# LargeDummyDevice register map
File version: 1.0
Registers are 32-bit, read-write, no defined reset value unless marked. A register's access mark holds for its fields unless they carry their own. Offsets are from the block's base; [hi:lo] are bit positions.

## PERIPHERAL_57
Base 0x40038000
0x04 REG_1 — Register 1
  [34:31] FIELD_1, [31:29] FIELD_4, [32:29] FIELD_6, [27:24] FIELD_5, [8] FIELD_2, [10:8] FIELD_3
0x08 REG_2 — Register 2
  [32:31] FIELD_2, [31] FIELD_11, [33:29] FIELD_4, [30:29] FIELD_13, [27:24] FIELD_18, [23] FIELD_12, [25:22] FIELD_5, [22] FIELD_16, [21] FIELD_3, [15:13] FIELD_15, [12] FIELD_17, [14:10] FIELD_10, [11:9] FIELD_14, [12:8] FIELD_7, [9:7] FIELD_1, [10:6] FIELD_19, [7:4] FIELD_8, [5:3] FIELD_6, [6:2] FIELD_9
0x0C REG_3 — Register 3
  [29:28] FIELD_4, [26:23] FIELD_6, [25:22] FIELD_7, [13:12] FIELD_3, [13:11] FIELD_2, [5] FIELD_1, [4:2] FIELD_5, [2:0] FIELD_8, [0] FIELD_9
0x10 REG_4 — Register 4
  [31] FIELD_4, [34:30] FIELD_23, [26:23] FIELD_13, [24:22] FIELD_20, [24:21] FIELD_18, [19:18] FIELD_22, [20:17] FIELD_2, [16:15] FIELD_7, [15] FIELD_15, [16:12] FIELD_9, [16:12] FIELD_12, [13:9] FIELD_10, [10:8] FIELD_11, [11:8] FIELD_21, [7:5] FIELD_14, [7:4] FIELD_3, [8:4] FIELD_8, [6:3] FIELD_1, [3:2] FIELD_5, [6:2] FIELD_6, [3:2] FIELD_17, [4:1] FIELD_16, [2:1] FIELD_19
0x14 REG_5 — Register 5
  [20] FIELD_8, [23:19] FIELD_6, [19:18] FIELD_4, [18:16] FIELD_1, [12:11] FIELD_5, [12:11] FIELD_9, [14:10] FIELD_7, [12:9] FIELD_3, [10:8] FIELD_2
0x18 REG_6 — Register 6
  [20:18] FIELD_4, [18:17] FIELD_3, [13] FIELD_7, [13:11] FIELD_6, [12:10] FIELD_5, [10:9] FIELD_2, [10:6] FIELD_1
0x1C REG_7 — Register 7
  [27:26] FIELD_16, [23] FIELD_9, [23:22] FIELD_3, [22:19] FIELD_14, [19:18] FIELD_1, [18:15] FIELD_8, [16:14] FIELD_5, [13:12] FIELD_12, [15:12] FIELD_15, [13:10] FIELD_7, [14:10] FIELD_13, [9] FIELD_6, [11:7] FIELD_11, [5] FIELD_2, [3:2] FIELD_4, [3:2] FIELD_10
0x20 REG_8 — Register 8
  [30:28] FIELD_1, [27:26] FIELD_2, [26:24] FIELD_11, [24] FIELD_17, [23] FIELD_9, [26:22] FIELD_14, [22:21] FIELD_18, [24:20] FIELD_4, [20:18] FIELD_10, [20:18] FIELD_13, [19:16] FIELD_6, [19:16] FIELD_15, [14:12] FIELD_16, [10] FIELD_5, [8] FIELD_12, [7:4] FIELD_8, [4:1] FIELD_3, [4:1] FIELD_7
0x24 REG_9 — Register 9
  [32:28] FIELD_15, [27] FIELD_7, [28:25] FIELD_5, [24] FIELD_14, [24:23] FIELD_9, [27:23] FIELD_12, [21] FIELD_11, [21:20] FIELD_8, [22:19] FIELD_20, [19] FIELD_23, [17:14] FIELD_4, [18:14] FIELD_6, [16:12] FIELD_2, [16:12] FIELD_16, [15:11] FIELD_17, [9] FIELD_3, [6] FIELD_13, [9:6] FIELD_18, [6:5] FIELD_1, [6:4] FIELD_19, [8:4] FIELD_21, [2:1] FIELD_10, [4:0] FIELD_22
0x28 REG_10 — Register 10
  [31:28] FIELD_3, [32:28] FIELD_8, [28:27] FIELD_10, [26:22] FIELD_11, [22:20] FIELD_6, [21:20] FIELD_9, [19] FIELD_4, [16:15] FIELD_2, [15:14] FIELD_13, [15:11] FIELD_7, [9] FIELD_12, [6] FIELD_1, [7:5] FIELD_5
0x2C REG_11 — Register 11
  [33:31] FIELD_14, [30:29] FIELD_16, [31:28] FIELD_1, [30:27] FIELD_4, [27:26] FIELD_12, [23:22] FIELD_15, [23:21] FIELD_5, [21:19] FIELD_9, [15] FIELD_7, [12] FIELD_11, [11:10] FIELD_3, [11:10] FIELD_13, [12:9] FIELD_8, [12:9] FIELD_18, [9:8] FIELD_2, [6:2] FIELD_10, [1] FIELD_6, [2:0] FIELD_17
0x30 REG_12 — Register 12
  [33:29] FIELD_2, [21:19] FIELD_4, [7] FIELD_3, [7:4] FIELD_1
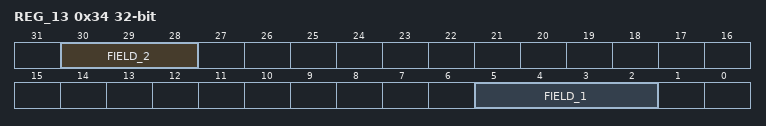
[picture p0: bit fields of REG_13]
0x34 REG_13 — Register 13
  [30:28] FIELD_2, [5:2] FIELD_1
0x38 REG_14 — Register 14
  [31] FIELD_19, [31:28] FIELD_11, [31:27] FIELD_15, [30:27] FIELD_18, [24:22] FIELD_16, [24:20] FIELD_2, [20] FIELD_8, [21:19] FIELD_4, [22:18] FIELD_5, [21:18] FIELD_7, [20:18] FIELD_9, [19:17] FIELD_14, [15] FIELD_12, [14] FIELD_3, [16:14] FIELD_22, [14:13] FIELD_1, [15:13] FIELD_20, [12] FIELD_6, [11] FIELD_21, [9:5] FIELD_10, [6:5] FIELD_13, [2] FIELD_17
0x3C REG_15 — Register 15
  [23] FIELD_1
0x40 REG_16 — Register 16
  [31:28] FIELD_14, [32:28] FIELD_20, [31:27] FIELD_18, [26:25] FIELD_21, [23] FIELD_2, [21] FIELD_4, [21] FIELD_10, [22:20] FIELD_3, [16:13] FIELD_1, [15:12] FIELD_6, [15:12] FIELD_8, [14:12] FIELD_16, [10] FIELD_17, [10:7] FIELD_15, [10:6] FIELD_5, [10:6] FIELD_11, [6:4] FIELD_7, [8:4] FIELD_13, [4:2] FIELD_12, [2] FIELD_19, [4:1] FIELD_9
0x44 REG_17 — Register 17
  [31] FIELD_7, [31] FIELD_16, [31:30] FIELD_25, [30:29] FIELD_27, [30:28] FIELD_10, [31:28] FIELD_13, [31:28] FIELD_28, [31:27] FIELD_4, [28:26] FIELD_1, [27:25] FIELD_20, [25:23] FIELD_15, [20] FIELD_11, [20] FIELD_24, [20:16] FIELD_23, [15] FIELD_9, [14] FIELD_5, [16:14] FIELD_22, [14:13] FIELD_2, [13] FIELD_6, [12] FIELD_12, [9] FIELD_21, [6:5] FIELD_8, [5:4] FIELD_3, [5:3] FIELD_17, [3] FIELD_18, [0] FIELD_14, [1:0] FIELD_19, [3:0] FIELD_26
0x48 REG_18 — Register 18
  [35:31] FIELD_6, [33:30] FIELD_4, [33:30] FIELD_25, [29:28] FIELD_19, [28] FIELD_28, [28:26] FIELD_11, [28:24] FIELD_9, [28:24] FIELD_13, [27:24] FIELD_17, [25:23] FIELD_1, [25:23] FIELD_23, [24:23] FIELD_24, [23:22] FIELD_14, [24:21] FIELD_5, [22:20] FIELD_21, [19:18] FIELD_2, [20:17] FIELD_27, [18:14] FIELD_12, [14] FIELD_16, [14:13] FIELD_7, [13:10] FIELD_26, [13:9] FIELD_15, [8] FIELD_3, [9:8] FIELD_29, [7:5] FIELD_18, [5] FIELD_20, [4:2] FIELD_10, [6:2] FIELD_22, [4:0] FIELD_8
0x4C REG_19 — Register 19
  [33:31] FIELD_4, [31:27] FIELD_2, [29:27] FIELD_6, [27:26] FIELD_1, [21:17] FIELD_7, [10:8] FIELD_5, [7] FIELD_8, [5:2] FIELD_3
0x50 REG_20 — Register 20
  [34:31] FIELD_3, [27] FIELD_2, [14] FIELD_4, [6] FIELD_1
0x54 REG_21 — Register 21
  [32:31] FIELD_3, [31:27] FIELD_1, [28:24] FIELD_11, [24] FIELD_14, [24:23] FIELD_4, [21] FIELD_18, [22:19] FIELD_6, [21:18] FIELD_5, [18] FIELD_12, [9] FIELD_2, [8] FIELD_13, [7] FIELD_17, [6:4] FIELD_16, [4:2] FIELD_7, [5:2] FIELD_8, [3:1] FIELD_10, [0] FIELD_9, [4:0] FIELD_15
0x58 REG_22 — Register 22
  [34:31] FIELD_6, [29:25] FIELD_1, [27:23] FIELD_3, [24:21] FIELD_5, [22:21] FIELD_8, [23:20] FIELD_2, [19] FIELD_4, [8:5] FIELD_7
0x5C REG_23 — Register 23
  [32:31] FIELD_1, [32:31] FIELD_19, [34:30] FIELD_4, [30:28] FIELD_5, [31:28] FIELD_7, [32:28] FIELD_11, [30:28] FIELD_16, [23:22] FIELD_22, [25:21] FIELD_13, [22:20] FIELD_3, [20] FIELD_17, [21:17] FIELD_28, [20:17] FIELD_30, [20:16] FIELD_8, [20:16] FIELD_12, [19:16] FIELD_20, [19:15] FIELD_21, [19:15] FIELD_23, [15:14] FIELD_25, [14:13] FIELD_24, [11] FIELD_27, [13:11] FIELD_29, [12:10] FIELD_10, [14:10] FIELD_31, [8] FIELD_15, [9:8] FIELD_26, [8:7] FIELD_14, [10:6] FIELD_2, [6:4] FIELD_18, [5:2] FIELD_9, [4:1] FIELD_6
0x60 REG_24 — Register 24
  [27:26] FIELD_5, [27:26] FIELD_6, [24:23] FIELD_2, [14:13] FIELD_3, [14:12] FIELD_7, [4:1] FIELD_4, [3:0] FIELD_1
0x64 REG_25 — Register 25
  [31] FIELD_1, [35:31] FIELD_3, [31] FIELD_22, [34:31] FIELD_25, [31:30] FIELD_7, [33:30] FIELD_13, [31:29] FIELD_20, [29:27] FIELD_2, [30:27] FIELD_11, [28:26] FIELD_9, [26] FIELD_23, [27:24] FIELD_12, [27:23] FIELD_19, [22:21] FIELD_16, [19] FIELD_21, [20:16] FIELD_17, [18:14] FIELD_6, [14:12] FIELD_8, [13:11] FIELD_4, [14:11] FIELD_14, [15:11] FIELD_15, [13:9] FIELD_26, [6:4] FIELD_10, [3] FIELD_18, [6:3] FIELD_24, [1:0] FIELD_5
0x68 REG_26 — Register 26
  [34:30] FIELD_5, [31:28] FIELD_1, [31:28] FIELD_12, [29:26] FIELD_10, [25] FIELD_7, [24] FIELD_13, [19] FIELD_3, [22:19] FIELD_9, [22:18] FIELD_8, [15] FIELD_11, [14:13] FIELD_15, [12:11] FIELD_16, [10] FIELD_4, [8:4] FIELD_2, [3] FIELD_6, [3:2] FIELD_14
0x6C REG_27 — Register 27
  [33:31] FIELD_1, [30:26] FIELD_5, [24:21] FIELD_13, [22:20] FIELD_11, [16] FIELD_6, [20:16] FIELD_8, [16] FIELD_10, [12] FIELD_9, [11:10] FIELD_12, [8:5] FIELD_2, [1] FIELD_3, [3:1] FIELD_4, [4:0] FIELD_7
0x70 REG_28 — Register 28
  [35:31] FIELD_12, [33:30] FIELD_1, [28] FIELD_7, [30:28] FIELD_16, [29:26] FIELD_9, [27:24] FIELD_23, [22] FIELD_3, [25:22] FIELD_8, [26:22] FIELD_11, [24:22] FIELD_13, [26:22] FIELD_22, [24:21] FIELD_21, [21] FIELD_24, [23:19] FIELD_19, [21:17] FIELD_14, [16] FIELD_17, [16:13] FIELD_6, [14:12] FIELD_4, [14:12] FIELD_5, [12:11] FIELD_15, [12:8] FIELD_20, [9:6] FIELD_2, [6:5] FIELD_10, [7:4] FIELD_18
0x74 REG_29 — Register 29
  [31] FIELD_6, [31] FIELD_17, [34:30] FIELD_4, [30] FIELD_5, [30:29] FIELD_10, [31:27] FIELD_9, [28:27] FIELD_11, [22:21] FIELD_1, [23:20] FIELD_12, [20] FIELD_16, [18] FIELD_2, [16] FIELD_13, [19:15] FIELD_14, [15:13] FIELD_15, [11:7] FIELD_8, [8:7] FIELD_18, [8:5] FIELD_3, [1] FIELD_7
0x78 REG_30 — Register 30
  [35:31] FIELD_6, [34:31] FIELD_12, [33:29] FIELD_13, [30:27] FIELD_21, [28:25] FIELD_2, [26:23] FIELD_4, [20] FIELD_5, [20:18] FIELD_24, [17] FIELD_16, [19:16] FIELD_8, [18:15] FIELD_1, [13:12] FIELD_22, [13:11] FIELD_18, [14:10] FIELD_11, [10:9] FIELD_9, [7] FIELD_10, [8:6] FIELD_3, [8:4] FIELD_7, [7:3] FIELD_19, [6:2] FIELD_17, [5:1] FIELD_15, [5:1] FIELD_23, [3:0] FIELD_14, [3:0] FIELD_20
0x7C REG_31 — Register 31
  [28:24] FIELD_28, [26:22] FIELD_11, [24:22] FIELD_14, [23:22] FIELD_23, [22:21] FIELD_20, [21:20] FIELD_17, [22:18] FIELD_2, [19:16] FIELD_25, [17:14] FIELD_15, [16:13] FIELD_3, [13] FIELD_5, [11] FIELD_13, [10] FIELD_19, [10:9] FIELD_18, [12:9] FIELD_26, [11:8] FIELD_9, [8] FIELD_12, [9:7] FIELD_4, [9:7] FIELD_16, [6] FIELD_6, [7:6] FIELD_8, [9:6] FIELD_24, [6] FIELD_27, [8:5] FIELD_1, [7:5] FIELD_22, [6:4] FIELD_10, [7:3] FIELD_29, [5:2] FIELD_21, [2:0] FIELD_7
0x80 REG_32 — Register 32
  [30:29] FIELD_29, [29:28] FIELD_10, [28] FIELD_32, [27] FIELD_9, [30:27] FIELD_26, [30:26] FIELD_2, [26] FIELD_8, [26] FIELD_23, [27:25] FIELD_11, [27:25] FIELD_21, [26:24] FIELD_12, [24] FIELD_19, [26:24] FIELD_31, [25:22] FIELD_1, [24:21] FIELD_17, [23:20] FIELD_28, [21:18] FIELD_18, [20:16] FIELD_13, [16] FIELD_20, [16:14] FIELD_6, [18:14] FIELD_14, [17:13] FIELD_4, [16:13] FIELD_16, [14:12] FIELD_24, [14:11] FIELD_30, [11:9] FIELD_25, [11:9] FIELD_27, [11:7] FIELD_22, [9:6] FIELD_5, [7:6] FIELD_7, [4] FIELD_3, [4:1] FIELD_15
0x84 REG_33 — Register 33
  [34:31] FIELD_4, [30] FIELD_14, [34:30] FIELD_19, [33:30] FIELD_26, [29] FIELD_18, [32:28] FIELD_8, [30:28] FIELD_17, [24] FIELD_10, [21] FIELD_5, [23:21] FIELD_11, [22:20] FIELD_27, [20:19] FIELD_1, [23:19] FIELD_22, [19:16] FIELD_3, [15] FIELD_12, [15:14] FIELD_20, [17:13] FIELD_15, [17:13] FIELD_23, [15:11] FIELD_2, [13:11] FIELD_13, [13:10] FIELD_6, [10:9] FIELD_24, [12:9] FIELD_28, [6:5] FIELD_7, [4] FIELD_16, [7:4] FIELD_29, [6:2] FIELD_9, [3:2] FIELD_21, [5:2] FIELD_25
0x88 REG_34 — Register 34
  [34:30] FIELD_6, [26:24] FIELD_4, [23] FIELD_5, [20:16] FIELD_8, [20:16] FIELD_9, [20:16] FIELD_10, [11] FIELD_7, [9:8] FIELD_3, [6:4] FIELD_1, [1] FIELD_2
0x8C REG_35 — Register 35
  [33:31] FIELD_6, [31:28] FIELD_8, [26] FIELD_18, [28:25] FIELD_4, [25] FIELD_21, [25] FIELD_24, [27:25] FIELD_25, [23:22] FIELD_14, [23:19] FIELD_20, [22:18] FIELD_12, [18] FIELD_26, [17:14] FIELD_5, [16:14] FIELD_27, [12:11] FIELD_17, [8] FIELD_3, [10:8] FIELD_11, [8] FIELD_15, [10:8] FIELD_16, [8:7] FIELD_19, [6] FIELD_1, [6] FIELD_9, [5] FIELD_2, [8:5] FIELD_13, [7:3] FIELD_7, [6:3] FIELD_22, [2:1] FIELD_10, [2:0] FIELD_23
0x90 REG_36 — Register 36
  [33:31] FIELD_6, [29] FIELD_2, [31:29] FIELD_11, [29:26] FIELD_12, [29:25] FIELD_4, [23:21] FIELD_1, [25:21] FIELD_5, [19:18] FIELD_18, [19:17] FIELD_15, [15:14] FIELD_9, [14:11] FIELD_10, [12:11] FIELD_14, [12:10] FIELD_13, [9] FIELD_16, [9:7] FIELD_8, [6:5] FIELD_3, [5:4] FIELD_17, [1] FIELD_7
0x94 REG_37 — Register 37
  [32:31] FIELD_9, [33:31] FIELD_10, [33:30] FIELD_3, [27] FIELD_4, [22:21] FIELD_6, [22:20] FIELD_11, [18] FIELD_2, [21:17] FIELD_1, [16:14] FIELD_7, [12:11] FIELD_8, [9:8] FIELD_5
0x98 REG_38 — Register 38
  [23] FIELD_1
0x9C REG_39 — Register 39
  [28] FIELD_14, [30:27] FIELD_3, [30:27] FIELD_15, [29:26] FIELD_17, [24:22] FIELD_7, [20:19] FIELD_6, [19:18] FIELD_10, [17:15] FIELD_1, [19:15] FIELD_11, [19:15] FIELD_16, [14] FIELD_8, [13] FIELD_12, [12:8] FIELD_4, [5:4] FIELD_13, [4:1] FIELD_9, [1:0] FIELD_2, [3:0] FIELD_5
